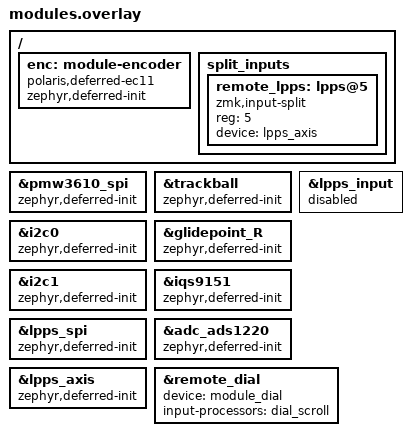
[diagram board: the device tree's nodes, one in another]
#include "../../boards/shields/GeaconPolaris/modules/trackball_right.dtsi"
&pmw3610_spi { zephyr,deferred-init; };
&trackball { zephyr,deferred-init; };
#include "../../boards/shields/GeaconPolaris/modules/cirque_right.dtsi"
&i2c0 { zephyr,deferred-init; };
&glidepoint_R { zephyr,deferred-init; };
/* IQS has different SCL/SDA pins from the Cirque pad. */
#define i2c0 i2c1
#define i2c0_default iqs_default
#define i2c0_sleep iqs_sleep
#include "../../boards/shields/GeaconPolaris/modules/iqs9151.dtsi"
#undef i2c0_sleep
#undef i2c0_default
#undef i2c0
&i2c1 { zephyr,deferred-init; };
&iqs9151 { zephyr,deferred-init; };

#include "../../boards/shields/GeaconPolaris/zeroshift_dial.dtsi"

/ { enc: module-encoder { compatible = "polaris,deferred-ec11", "alps,ec11"; zephyr,deferred-init; }; };
#define left_encoder enc
#include "../../boards/shields/GeaconPolaris/modules/encoder.dtsi"
#undef left_encoder
#include "../../boards/shields/GeaconPolaris/modules/lpps.dtsi"
&lpps_spi { zephyr,deferred-init; };
&adc_ads1220 { zephyr,deferred-init; };
&lpps_axis { zephyr,deferred-init; };
&lpps_input { status = "disabled"; };
/ { split_inputs { remote_lpps: lpps@5 { compatible = "zmk,input-split"; reg = <5>; }; }; };
&remote_lpps { device = <&lpps_axis>; };

&remote_dial {
    device = <&module_dial>;
    input-processors = <&dial_scroll>;
};
